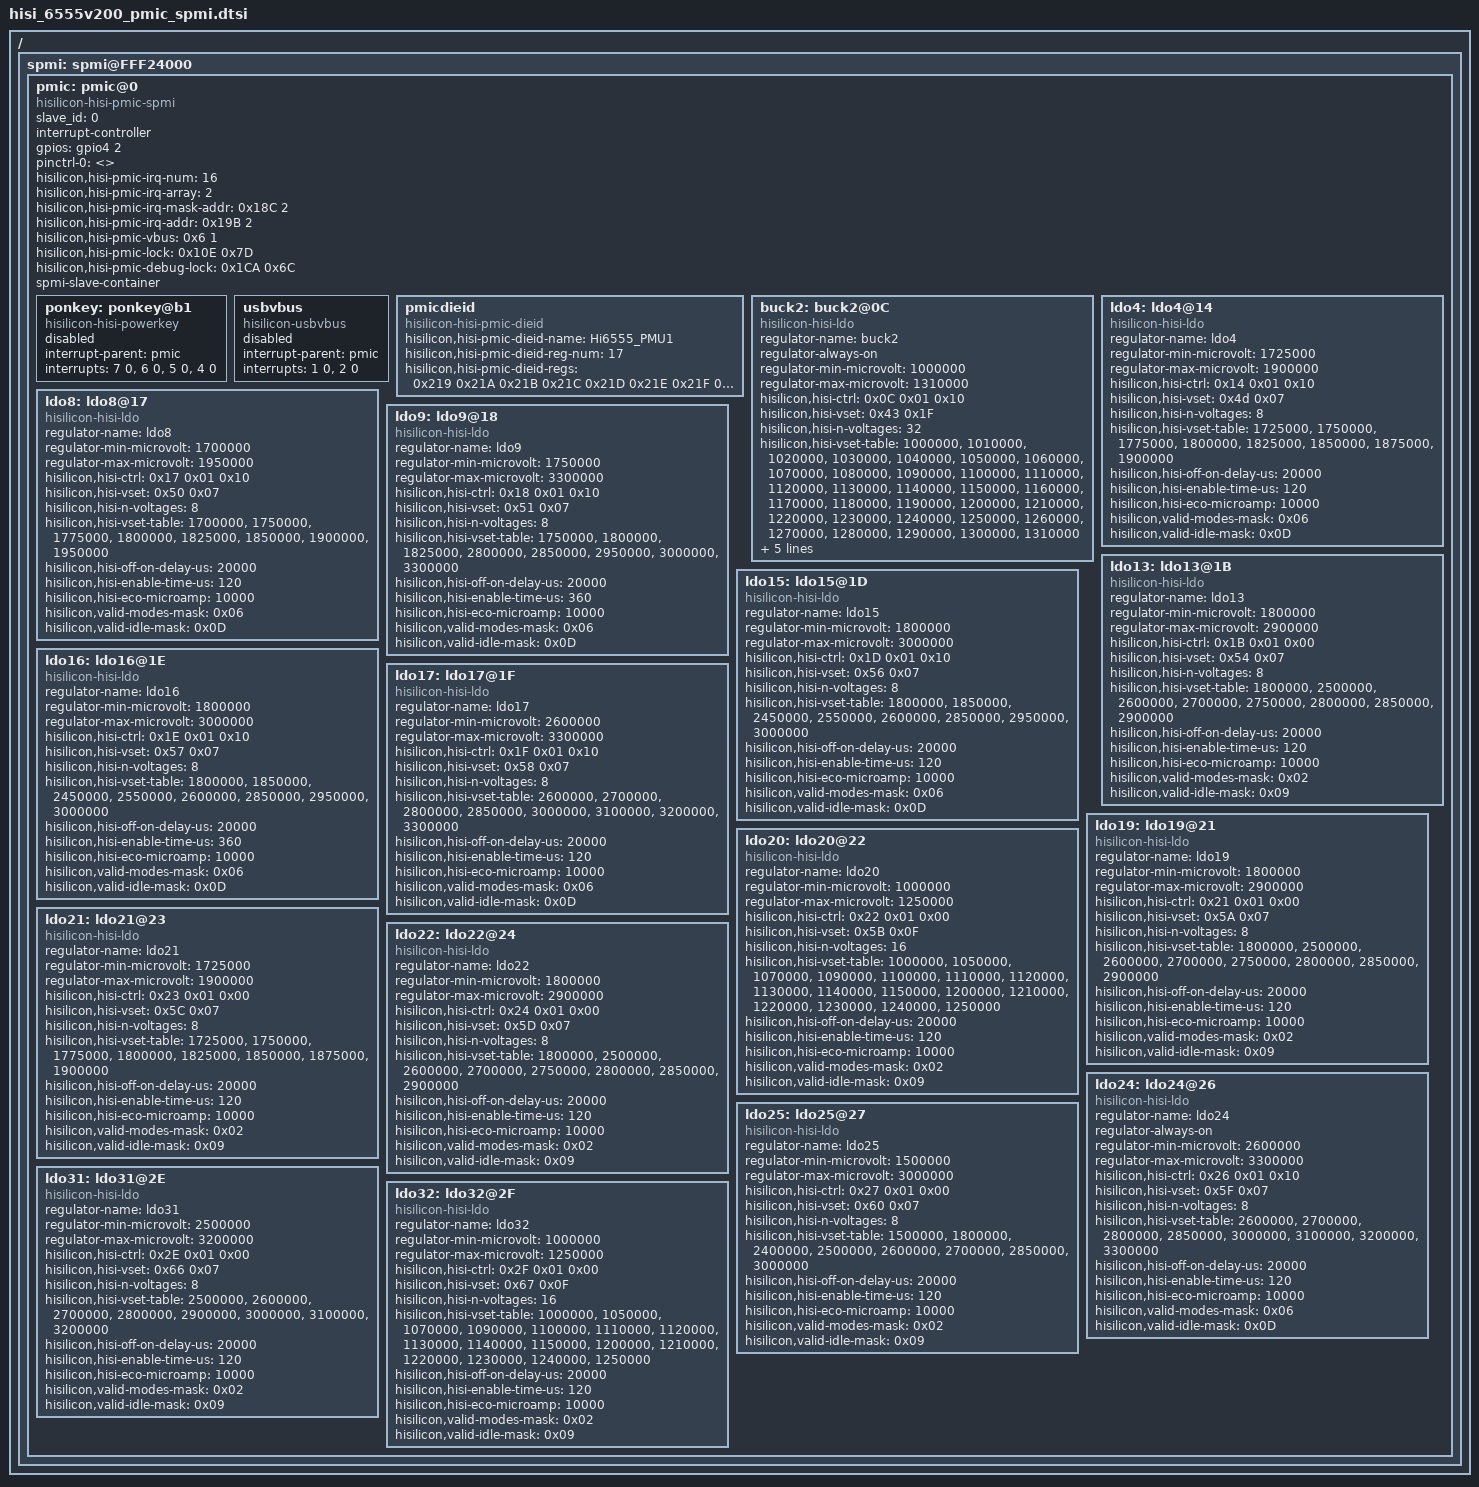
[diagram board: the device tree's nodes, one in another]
/*
 *  Copyright (C) 2012-2013 Linaro Ltd.
 *
 *  This program is free software; you can redistribute it and/or modify
 *  it under the terms of the GNU General Public License version 2 as
 *  publishhed by the Free Software Foundation.
 */
 /*hisilicon,valid-modes-mask:
*#define REGULATOR_MODE_FAST                     0x1
*#define REGULATOR_MODE_NORMAL                   0x2
*#define REGULATOR_MODE_IDLE                     0x4
*#define REGULATOR_MODE_STANDBY                  0x8
*/
/*hisilicon,valid-idle-mask:
*#define REGULATOR_CHANGE_VOLTAGE        0x1
*#define REGULATOR_CHANGE_CURRENT        0x2
*#define REGULATOR_CHANGE_MODE           0x4
*#define REGULATOR_CHANGE_STATUS         0x8
*#define REGULATOR_CHANGE_DRMS           0x10
*#define REGULATOR_CHANGE_BYPASS         0x20
*/
/ {
	spmi: spmi@FFF24000 {
		pmic: pmic@0 {
			compatible = "hisilicon-hisi-pmic-spmi";
			slave_id = <0>;
			#interrupt-cells = <2>;
			interrupt-controller;
			gpios = <&gpio4 2 0>;
			pinctrl-names = "default";
			pinctrl-0 = <>;
			hisilicon,hisi-pmic-irq-num = <16>;/*hisi irq number*/
			hisilicon,hisi-pmic-irq-array = <2>;/*hisi irq array*/
			hisilicon,hisi-pmic-irq-mask-addr = <0x18C 2>;/*hisi irq mask addr*/
			hisilicon,hisi-pmic-irq-addr = <0x19B 2>;/*hisi irq addr*/
			hisilicon,hisi-pmic-vbus = <0x6 1>;/*vbus status addr and bit*/
			hisilicon,hisi-pmic-lock = <0x10E 0x7D>; /*lock: <addr value>*/
			hisilicon,hisi-pmic-debug-lock = <0x1CA 0x6C>;/*debug-lock: <addr value>*/
			spmi-slave-container;/*spmi-dev-container;*/

			ponkey:ponkey@b1{
					compatible = "hisilicon-hisi-powerkey";
					interrupt-parent = <&pmic>;
					interrupts = <7 0>, <6 0>, <5 0>, <4 0>;
					interrupt-names = "down", "up", "hold 1s", "hold 6s";
					status = "disabled";
			};

			usbvbus {
				compatible = "hisilicon-usbvbus";
				interrupt-parent = <&pmic>;
				interrupts = <1 0>, <2 0>;
				interrupt-names = "connect", "disconnect";
				status = "disabled";
			};

			pmicdieid {
				compatible = "hisilicon-hisi-pmic-dieid";
				hisilicon,hisi-pmic-dieid-name = "Hi6555_PMU1"; /*dieid: <chip name>*/
				hisilicon,hisi-pmic-dieid-reg-num = <17>; /*dieid: <register number>*/
				hisilicon,hisi-pmic-dieid-regs = <0x219 0x21A 0x21B 0x21C 0x21D 0x21E 0x21F 0x220 0x221 0x222 0x223 0x224 0x225 0x226 0x227 0x228 0x229>; /*dieid: <addr value>*/
			};

			buck2: buck2@0C {
				compatible = "hisilicon-hisi-ldo";
				regulator-name = "buck2";
				regulator-always-on;
				regulator-min-microvolt = <1000000>;
				regulator-max-microvolt = <1310000>;
				hisilicon,hisi-ctrl = <0x0C 0x01 0x10>;/*ctrl_reg、enable_mask、eco_mode_mask*/
				hisilicon,hisi-vset = <0x43 0x1F>;
				hisilicon,hisi-n-voltages = <32>;
				hisilicon,hisi-vset-table = <1000000>, <1010000>,
											<1020000>, <1030000>,
											<1040000>, <1050000>,
											<1060000>, <1070000>,
											<1080000>, <1090000>,
											<1100000>, <1110000>,
											<1120000>, <1130000>,
											<1140000>, <1150000>,
											<1160000>, <1170000>,
											<1180000>, <1190000>,
											<1200000>, <1210000>,
											<1220000>, <1230000>,
											<1240000>, <1250000>,
											<1260000>, <1270000>,
											<1280000>, <1290000>,
											<1300000>, <1310000>;
				hisilicon,hisi-off-on-delay-us = <20000>;
				hisilicon,hisi-enable-time-us = <480>;
				hisilicon,hisi-eco-microamp = <10000>;
				hisilicon,valid-modes-mask = <0x06>;
				hisilicon,valid-idle-mask = <0x0D>;
			};

			ldo4: ldo4@14 {
				compatible = "hisilicon-hisi-ldo";
				regulator-name = "ldo4";
				regulator-min-microvolt = <1725000>;
				regulator-max-microvolt = <1900000>;
				hisilicon,hisi-ctrl = <0x14 0x01 0x10>;/*ctrl_reg、enable_mask、eco_mode_mask*/
				hisilicon,hisi-vset = <0x4d 0x07>;
				hisilicon,hisi-n-voltages = <8>;
				hisilicon,hisi-vset-table = <1725000>, <1750000>,
											<1775000>, <1800000>,
											<1825000>, <1850000>,
											<1875000>, <1900000>;
				hisilicon,hisi-off-on-delay-us = <20000>;
				hisilicon,hisi-enable-time-us = <120>;
				hisilicon,hisi-eco-microamp = <10000>;
				hisilicon,valid-modes-mask = <0x06>;
				hisilicon,valid-idle-mask = <0x0D>;
			};

			ldo8: ldo8@17 {
				compatible = "hisilicon-hisi-ldo";
				regulator-name = "ldo8";
				regulator-min-microvolt = <1700000>;
				regulator-max-microvolt = <1950000>;
				hisilicon,hisi-ctrl = <0x17 0x01 0x10>;/*ctrl_reg、enable_mask、eco_mode_mask*/
				hisilicon,hisi-vset = <0x50 0x07>;
				hisilicon,hisi-n-voltages = <8>;
				hisilicon,hisi-vset-table = <1700000>, <1750000>,
											<1775000>, <1800000>,
											<1825000>, <1850000>,
											<1900000>, <1950000>;
				hisilicon,hisi-off-on-delay-us = <20000>;
				hisilicon,hisi-enable-time-us = <120>;
				hisilicon,hisi-eco-microamp = <10000>;
				hisilicon,valid-modes-mask = <0x06>;
				hisilicon,valid-idle-mask = <0x0D>;
			};

			ldo9: ldo9@18 {
				compatible = "hisilicon-hisi-ldo";
				regulator-name = "ldo9";
				regulator-min-microvolt = <1750000>;
				regulator-max-microvolt = <3300000>;
				hisilicon,hisi-ctrl = <0x18 0x01 0x10>;
				hisilicon,hisi-vset = <0x51 0x07>;
				hisilicon,hisi-n-voltages = <8>;
				hisilicon,hisi-vset-table = <1750000>, <1800000>,
											<1825000>, <2800000>,
											<2850000>, <2950000>,
											<3000000>, <3300000>;
				hisilicon,hisi-off-on-delay-us = <20000>;
				hisilicon,hisi-enable-time-us = <360>;
				hisilicon,hisi-eco-microamp = <10000>;
				hisilicon,valid-modes-mask = <0x06>;
				hisilicon,valid-idle-mask = <0x0D>;
			};

			ldo13: ldo13@1B {
				compatible = "hisilicon-hisi-ldo";
				regulator-name = "ldo13";
				regulator-min-microvolt = <1800000>;
				regulator-max-microvolt = <2900000>;
				hisilicon,hisi-ctrl = <0x1B 0x01 0x00>;
				hisilicon,hisi-vset = <0x54 0x07>;
				hisilicon,hisi-n-voltages = <8>;
				hisilicon,hisi-vset-table = <1800000>, <2500000>,
											<2600000>, <2700000>,
											<2750000>, <2800000>,
											<2850000>, <2900000>;
				hisilicon,hisi-off-on-delay-us = <20000>;
				hisilicon,hisi-enable-time-us = <120>;
				hisilicon,hisi-eco-microamp = <10000>;
				hisilicon,valid-modes-mask = <0x02>;
				hisilicon,valid-idle-mask = <0x09>;
			};


			ldo15: ldo15@1D {
				compatible = "hisilicon-hisi-ldo";
				regulator-name = "ldo15";
				regulator-min-microvolt = <1800000>;
				regulator-max-microvolt = <3000000>;
				hisilicon,hisi-ctrl = <0x1D 0x01 0x10>;
				hisilicon,hisi-vset = <0x56 0x07>;
				hisilicon,hisi-n-voltages = <8>;
				hisilicon,hisi-vset-table = <1800000>, <1850000>,
											<2450000>, <2550000>,
											<2600000>, <2850000>,
											<2950000>, <3000000>;
				hisilicon,hisi-off-on-delay-us = <20000>;
				hisilicon,hisi-enable-time-us = <120>;
				hisilicon,hisi-eco-microamp = <10000>;
				hisilicon,valid-modes-mask = <0x06>;
				hisilicon,valid-idle-mask = <0x0D>;
			};

			ldo16: ldo16@1E {
				compatible = "hisilicon-hisi-ldo";
				regulator-name = "ldo16";
				regulator-min-microvolt = <1800000>;
				regulator-max-microvolt = <3000000>;
				hisilicon,hisi-ctrl = <0x1E 0x01 0x10>;
				hisilicon,hisi-vset = <0x57 0x07>;
				hisilicon,hisi-n-voltages = <8>;
				hisilicon,hisi-vset-table = <1800000>, <1850000>,
											<2450000>, <2550000>,
											<2600000>, <2850000>,
											<2950000>, <3000000>;
				hisilicon,hisi-off-on-delay-us = <20000>;
				hisilicon,hisi-enable-time-us = <360>;
				hisilicon,hisi-eco-microamp = <10000>;
				hisilicon,valid-modes-mask = <0x06>;
				hisilicon,valid-idle-mask = <0x0D>;
			};

			ldo17: ldo17@1F {
				compatible = "hisilicon-hisi-ldo";
				regulator-name = "ldo17";
				regulator-min-microvolt = <2600000>;
				regulator-max-microvolt = <3300000>;
				hisilicon,hisi-ctrl = <0x1F 0x01 0x10>;
				hisilicon,hisi-vset = <0x58 0x07>;
				hisilicon,hisi-n-voltages = <8>;
				hisilicon,hisi-vset-table = <2600000>, <2700000>,
											<2800000>, <2850000>,
											<3000000>, <3100000>,
											<3200000>, <3300000>;
				hisilicon,hisi-off-on-delay-us = <20000>;
				hisilicon,hisi-enable-time-us = <120>;
				hisilicon,hisi-eco-microamp = <10000>;
				hisilicon,valid-modes-mask = <0x06>;
				hisilicon,valid-idle-mask = <0x0D>;
			};

			ldo19: ldo19@21 {
				compatible = "hisilicon-hisi-ldo";
				regulator-name = "ldo19";
				regulator-min-microvolt = <1800000>;
				regulator-max-microvolt = <2900000>;
				hisilicon,hisi-ctrl = <0x21 0x01 0x00>;
				hisilicon,hisi-vset = <0x5A 0x07>;
				hisilicon,hisi-n-voltages = <8>;
				hisilicon,hisi-vset-table = <1800000>, <2500000>,
											<2600000>, <2700000>,
											<2750000>, <2800000>,
											<2850000>, <2900000>;
				hisilicon,hisi-off-on-delay-us = <20000>;
				hisilicon,hisi-enable-time-us = <120>;
				hisilicon,hisi-eco-microamp = <10000>;
				hisilicon,valid-modes-mask = <0x02>;
				hisilicon,valid-idle-mask = <0x09>;
			};

			ldo20: ldo20@22 {
				compatible = "hisilicon-hisi-ldo";
				regulator-name = "ldo20";
				regulator-min-microvolt = <1000000>;
				regulator-max-microvolt = <1250000>;
				hisilicon,hisi-ctrl = <0x22 0x01 0x00>;
				hisilicon,hisi-vset = <0x5B 0x0F>;
				hisilicon,hisi-n-voltages = <16>;
				hisilicon,hisi-vset-table = <1000000>, <1050000>,
											<1070000>, <1090000>,
											<1100000>, <1110000>,
											<1120000>, <1130000>,
											<1140000>, <1150000>,
											<1200000>, <1210000>,
											<1220000>, <1230000>,
											<1240000>, <1250000>;
				hisilicon,hisi-off-on-delay-us = <20000>;
				hisilicon,hisi-enable-time-us = <120>;
				hisilicon,hisi-eco-microamp = <10000>;
				hisilicon,valid-modes-mask = <0x02>;
				hisilicon,valid-idle-mask = <0x09>;
			};

			ldo21: ldo21@23 {
				compatible = "hisilicon-hisi-ldo";
				regulator-name = "ldo21";
				regulator-min-microvolt = <1725000>;
				regulator-max-microvolt = <1900000>;
				hisilicon,hisi-ctrl = <0x23 0x01 0x00>;
				hisilicon,hisi-vset = <0x5C 0x07>;
				hisilicon,hisi-n-voltages = <8>;
				hisilicon,hisi-vset-table = <1725000>, <1750000>,
											<1775000>, <1800000>,
											<1825000>, <1850000>,
											<1875000>, <1900000>;
				hisilicon,hisi-off-on-delay-us = <20000>;
				hisilicon,hisi-enable-time-us = <120>;
				hisilicon,hisi-eco-microamp = <10000>;
				hisilicon,valid-modes-mask = <0x02>;
				hisilicon,valid-idle-mask = <0x09>;
			};

			ldo22: ldo22@24 {
				compatible = "hisilicon-hisi-ldo";
				regulator-name = "ldo22";
				regulator-min-microvolt = <1800000>;
				regulator-max-microvolt = <2900000>;
				hisilicon,hisi-ctrl = <0x24 0x01 0x00>;
				hisilicon,hisi-vset = <0x5D 0x07>;
				hisilicon,hisi-n-voltages = <8>;
				hisilicon,hisi-vset-table = <1800000>, <2500000>,
											<2600000>, <2700000>,
											<2750000>, <2800000>,
											<2850000>, <2900000>;
				hisilicon,hisi-off-on-delay-us = <20000>;
				hisilicon,hisi-enable-time-us = <120>;
				hisilicon,hisi-eco-microamp = <10000>;
				hisilicon,valid-modes-mask = <0x02>;
				hisilicon,valid-idle-mask = <0x09>;
			};

			ldo24: ldo24@26 {
				compatible = "hisilicon-hisi-ldo";
				regulator-name = "ldo24";
				regulator-always-on;
				regulator-min-microvolt = <2600000>;
				regulator-max-microvolt = <3300000>;
				hisilicon,hisi-ctrl = <0x26 0x01 0x10>;
				hisilicon,hisi-vset = <0x5F 0x07>;
				hisilicon,hisi-n-voltages = <8>;
				hisilicon,hisi-vset-table = <2600000>, <2700000>,
											<2800000>, <2850000>,
											<3000000>, <3100000>,
											<3200000>, <3300000>;
				hisilicon,hisi-off-on-delay-us = <20000>;
				hisilicon,hisi-enable-time-us = <120>;
				hisilicon,hisi-eco-microamp = <10000>;
				hisilicon,valid-modes-mask = <0x06>;
				hisilicon,valid-idle-mask = <0x0D>;
			};


			ldo25: ldo25@27 {
				compatible = "hisilicon-hisi-ldo";
				regulator-name = "ldo25";
				regulator-min-microvolt = <1500000>;
				regulator-max-microvolt = <3000000>;
				hisilicon,hisi-ctrl = <0x27 0x01 0x00>;
				hisilicon,hisi-vset = <0x60 0x07>;
				hisilicon,hisi-n-voltages = <8>;
				hisilicon,hisi-vset-table = <1500000>, <1800000>,
											<2400000>, <2500000>,
											<2600000>, <2700000>,
											<2850000>, <3000000>;
				hisilicon,hisi-off-on-delay-us = <20000>;
				hisilicon,hisi-enable-time-us = <120>;
				hisilicon,hisi-eco-microamp = <10000>;
				hisilicon,valid-modes-mask = <0x02>;
				hisilicon,valid-idle-mask = <0x09>;
			};

			ldo31: ldo31@2E {
				compatible = "hisilicon-hisi-ldo";
				regulator-name = "ldo31";
				regulator-min-microvolt = <2500000>;
				regulator-max-microvolt = <3200000>;
				hisilicon,hisi-ctrl = <0x2E 0x01 0x00>;
				hisilicon,hisi-vset = <0x66 0x07>;
				hisilicon,hisi-n-voltages = <8>;
				hisilicon,hisi-vset-table = <2500000>, <2600000>,
											<2700000>, <2800000>,
											<2900000>, <3000000>,
											<3100000>, <3200000>;
				hisilicon,hisi-off-on-delay-us = <20000>;
				hisilicon,hisi-enable-time-us = <120>;
				hisilicon,hisi-eco-microamp = <10000>;
				hisilicon,valid-modes-mask = <0x02>;
				hisilicon,valid-idle-mask = <0x09>;
			};

			ldo32: ldo32@2F {
				compatible = "hisilicon-hisi-ldo";
				regulator-name = "ldo32";
				regulator-min-microvolt = <1000000>;
				regulator-max-microvolt = <1250000>;
				hisilicon,hisi-ctrl = <0x2F 0x01 0x00>;
				hisilicon,hisi-vset = <0x67 0x0F>;
				hisilicon,hisi-n-voltages = <16>;
				hisilicon,hisi-vset-table = <1000000>, <1050000>,
											<1070000>, <1090000>,
											<1100000>, <1110000>,
											<1120000>, <1130000>,
											<1140000>, <1150000>,
											<1200000>, <1210000>,
											<1220000>, <1230000>,
											<1240000>, <1250000>;
				hisilicon,hisi-off-on-delay-us = <20000>;
				hisilicon,hisi-enable-time-us = <120>;
				hisilicon,hisi-eco-microamp = <10000>;
				hisilicon,valid-modes-mask = <0x02>;
				hisilicon,valid-idle-mask = <0x09>;
			};
		};/* end of pmic */
	};/*end of spmi*/
};
